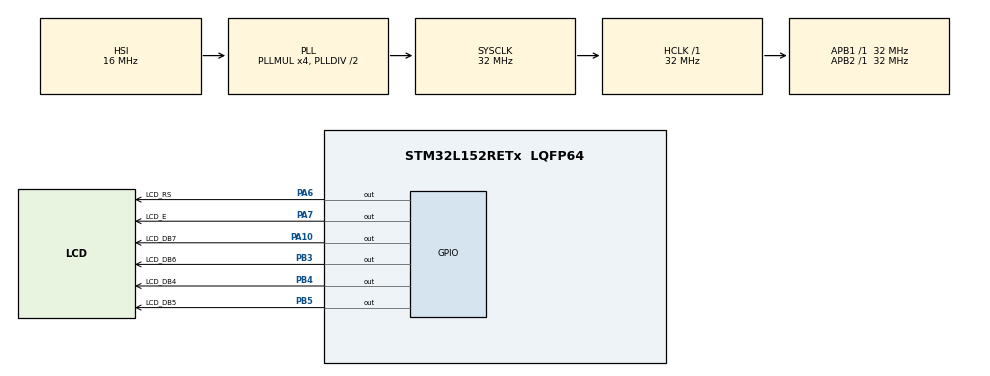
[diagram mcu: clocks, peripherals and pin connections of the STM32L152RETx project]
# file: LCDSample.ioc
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Mcu.Family=STM32L1
Mcu.Name=STM32L152RETx
Mcu.Package=LQFP64
NVIC.PriorityGroup=NVIC_PRIORITYGROUP_4
PA10.GPIO_Label=LCD_DB7
PA10.Signal=GPIO_Output
PA6.GPIO_Label=LCD_RS
PA6.Signal=GPIO_Output
PA7.GPIO_Label=LCD_E
PA7.Signal=GPIO_Output
PB3.GPIO_Label=LCD_DB6
PB3.Signal=GPIO_Output
PB4.GPIO_Label=LCD_DB4
PB4.Signal=GPIO_Output
PB5.GPIO_Label=LCD_DB5
PB5.Signal=GPIO_Output
ProjectManager.HeapSize=0x200
ProjectManager.StackSize=0x400
ProjectManager.TargetToolchain=SW4STM32
RCC.48MHZClocksFreq_Value=32000000
RCC.AHBFreq_Value=32000000
RCC.APB1Freq_Value=32000000
RCC.APB1TimFreq_Value=32000000
RCC.APB2Freq_Value=32000000
RCC.APB2TimFreq_Value=32000000
RCC.HCLKFreq_Value=32000000
RCC.HSE_VALUE=24000000
RCC.HSI_VALUE=16000000
RCC.LSE_VALUE=32768
RCC.MSI_VALUE=2097000
RCC.PLLMUL=RCC_PLL_MUL4
RCC.SYSCLKFreq_VALUE=32000000
RCC.SYSCLKSource=RCC_SYSCLKSOURCE_PLLCLK
RCC.VCOOutputFreq_Value=64000000
board=custom

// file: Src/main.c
/**
  ******************************************************************************
  * @file           : main.c
  * @brief          : Main program body
  ******************************************************************************
  ** This notice applies to any and all portions of this file
  * that are not between comment pairs USER CODE BEGIN and
  * USER CODE END. Other portions of this file, whether
  * inserted by the user or by software development tools
  * are owned by their respective copyright owners.
  *
  * COPYRIGHT(c) 2018 STMicroelectronics
  *
  * Redistribution and use in source and binary forms, with or without modification,
  * are permitted provided that the following conditions are met:
  *   1. Redistributions of source code must retain the above copyright notice,
  *      this list of conditions and the following disclaimer.
  *   2. Redistributions in binary form must reproduce the above copyright notice,
  *      this list of conditions and the following disclaimer in the documentation
  *      and/or other materials provided with the distribution.
  *   3. Neither the name of STMicroelectronics nor the names of its contributors
  *      may be used to endorse or promote products derived from this software
  *      without specific prior written permission.
  *
  * THIS SOFTWARE IS PROVIDED BY THE COPYRIGHT HOLDERS AND CONTRIBUTORS "AS IS"
  * AND ANY EXPRESS OR IMPLIED WARRANTIES, INCLUDING, BUT NOT LIMITED TO, THE
  * IMPLIED WARRANTIES OF MERCHANTABILITY AND FITNESS FOR A PARTICULAR PURPOSE ARE
  * DISCLAIMED. IN NO EVENT SHALL THE COPYRIGHT HOLDER OR CONTRIBUTORS BE LIABLE
  * FOR ANY DIRECT, INDIRECT, INCIDENTAL, SPECIAL, EXEMPLARY, OR CONSEQUENTIAL
  * DAMAGES (INCLUDING, BUT NOT LIMITED TO, PROCUREMENT OF SUBSTITUTE GOODS OR
  * SERVICES; LOSS OF USE, DATA, OR PROFITS; OR BUSINESS INTERRUPTION) HOWEVER
  * CAUSED AND ON ANY THEORY OF LIABILITY, WHETHER IN CONTRACT, STRICT LIABILITY,
  * OR TORT (INCLUDING NEGLIGENCE OR OTHERWISE) ARISING IN ANY WAY OUT OF THE USE
  * OF THIS SOFTWARE, EVEN IF ADVISED OF THE POSSIBILITY OF SUCH DAMAGE.
  *
  ******************************************************************************
  */
#include "main.h"
#include "stm32l1xx_hal.h"

/* USER CODE BEGIN PV */
/* Private variables ---------------------------------------------------------*/

/* USER CODE END PV */

void SystemClock_Config(void);
static void MX_GPIO_Init(void);

/* USER CODE BEGIN PFP */
/* Private function prototypes -----------------------------------------------*/

/* USER CODE END PFP */

/* USER CODE BEGIN 0 */
#include "lcd.h"

/* USER CODE END 0 */

int main(void)
{

  /* MCU Configuration----------------------------------------------------------*/

  /* Reset of all peripherals, Initializes the Flash interface and the Systick. */
  HAL_Init();

  /* Configure the system clock */
  SystemClock_Config();

  /* Initialize all configured peripherals */
  MX_GPIO_Init();
  /* USER CODE BEGIN 2 */

  LCD_Init();

  LCD_locate(0, 0);
  LCD_putc('A');
  LCD_putc('B');
  LCD_putc('C');
  LCD_putc('D');
  LCD_putc('E');

  LCD_locate(1, 0);
  LCD_putc('X');
  LCD_putc('Y');
  LCD_putc('Z');

  /* USER CODE END 2 */

  /* Infinite loop */
  while (1)
  {

  }

}

void SystemClock_Config(void)
{

  RCC_OscInitTypeDef RCC_OscInitStruct;
  RCC_ClkInitTypeDef RCC_ClkInitStruct;

    /**Configure the main internal regulator output voltage
    */
  __HAL_PWR_VOLTAGESCALING_CONFIG(PWR_REGULATOR_VOLTAGE_SCALE1);

    /**Initializes the CPU, AHB and APB busses clocks
    */
  RCC_OscInitStruct.OscillatorType = RCC_OSCILLATORTYPE_HSI;
  RCC_OscInitStruct.HSIState = RCC_HSI_ON;
  RCC_OscInitStruct.HSICalibrationValue = 16;
  RCC_OscInitStruct.PLL.PLLState = RCC_PLL_ON;
  RCC_OscInitStruct.PLL.PLLSource = RCC_PLLSOURCE_HSI;
  RCC_OscInitStruct.PLL.PLLMUL = RCC_PLL_MUL4;
  RCC_OscInitStruct.PLL.PLLDIV = RCC_PLL_DIV2;
  if (HAL_RCC_OscConfig(&RCC_OscInitStruct) != HAL_OK)
  {
    _Error_Handler(__FILE__, __LINE__);
  }

    /**Initializes the CPU, AHB and APB busses clocks
    */
  RCC_ClkInitStruct.ClockType = RCC_CLOCKTYPE_HCLK|RCC_CLOCKTYPE_SYSCLK
                              |RCC_CLOCKTYPE_PCLK1|RCC_CLOCKTYPE_PCLK2;
  RCC_ClkInitStruct.SYSCLKSource = RCC_SYSCLKSOURCE_PLLCLK;
  RCC_ClkInitStruct.AHBCLKDivider = RCC_SYSCLK_DIV1;
  RCC_ClkInitStruct.APB1CLKDivider = RCC_HCLK_DIV1;
  RCC_ClkInitStruct.APB2CLKDivider = RCC_HCLK_DIV1;

  if (HAL_RCC_ClockConfig(&RCC_ClkInitStruct, FLASH_LATENCY_1) != HAL_OK)
  {
    _Error_Handler(__FILE__, __LINE__);
  }

    /**Configure the Systick interrupt time
    */
  HAL_SYSTICK_Config(HAL_RCC_GetHCLKFreq()/1000);

    /**Configure the Systick
    */
  HAL_SYSTICK_CLKSourceConfig(SYSTICK_CLKSOURCE_HCLK);

  /* SysTick_IRQn interrupt configuration */
  HAL_NVIC_SetPriority(SysTick_IRQn, 0, 0);
}

/** Configure pins as
        * Analog
        * Input
        * Output
        * EVENT_OUT
        * EXTI
*/
static void MX_GPIO_Init(void)
{

  GPIO_InitTypeDef GPIO_InitStruct;

  /* GPIO Ports Clock Enable */
  __HAL_RCC_GPIOA_CLK_ENABLE();
  __HAL_RCC_GPIOB_CLK_ENABLE();

  /*Configure GPIO pin Output Level */
  HAL_GPIO_WritePin(GPIOA, LCD_RS_Pin|LCD_E_Pin|LCD_DB7_Pin, GPIO_PIN_RESET);

  /*Configure GPIO pin Output Level */
  HAL_GPIO_WritePin(GPIOB, LCD_DB6_Pin|LCD_DB4_Pin|LCD_DB5_Pin, GPIO_PIN_RESET);

  /*Configure GPIO pins : LCD_RS_Pin LCD_E_Pin LCD_DB7_Pin */
  GPIO_InitStruct.Pin = LCD_RS_Pin|LCD_E_Pin|LCD_DB7_Pin;
  GPIO_InitStruct.Mode = GPIO_MODE_OUTPUT_PP;
  GPIO_InitStruct.Pull = GPIO_NOPULL;
  GPIO_InitStruct.Speed = GPIO_SPEED_FREQ_LOW;
  HAL_GPIO_Init(GPIOA, &GPIO_InitStruct);

  /*Configure GPIO pins : LCD_DB6_Pin LCD_DB4_Pin LCD_DB5_Pin */
  GPIO_InitStruct.Pin = LCD_DB6_Pin|LCD_DB4_Pin|LCD_DB5_Pin;
  GPIO_InitStruct.Mode = GPIO_MODE_OUTPUT_PP;
  GPIO_InitStruct.Pull = GPIO_NOPULL;
  GPIO_InitStruct.Speed = GPIO_SPEED_FREQ_LOW;
  HAL_GPIO_Init(GPIOB, &GPIO_InitStruct);

}

void _Error_Handler(char *file, int line)
{
  while(1)
  {
  }
}

/************************ (C) COPYRIGHT STMicroelectronics *****END OF FILE****/
